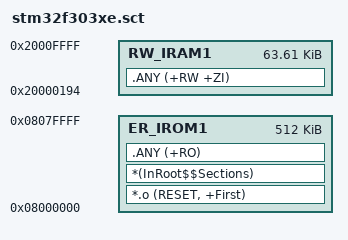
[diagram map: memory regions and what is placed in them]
; Scatter-Loading Description File
;;;;;;;;;;;;;;;;;;;;;;;;;;;;;;;;;;;;;;;;;;;;;;;;;;;;;;;;;;;;;;;;;;;;;;;;;;;;;;;;
; Copyright (c) 2014, STMicroelectronics
; All rights reserved.
;
; Redistribution and use in source and binary forms, with or without
; modification, are permitted provided that the following conditions are met:
;
; 1. Redistributions of source code must retain the above copyright notice,
;     this list of conditions and the following disclaimer.
; 2. Redistributions in binary form must reproduce the above copyright notice,
;    this list of conditions and the following disclaimer in the documentation
;    and/or other materials provided with the distribution.
; 3. Neither the name of STMicroelectronics nor the names of its contributors
;    may be used to endorse or promote products derived from this software
;    without specific prior written permission.
;
; THIS SOFTWARE IS PROVIDED BY THE COPYRIGHT HOLDERS AND CONTRIBUTORS "AS IS"
; AND ANY EXPRESS OR IMPLIED WARRANTIES, INCLUDING, BUT NOT LIMITED TO, THE
; IMPLIED WARRANTIES OF MERCHANTABILITY AND FITNESS FOR A PARTICULAR PURPOSE ARE
; DISCLAIMED. IN NO EVENT SHALL THE COPYRIGHT HOLDER OR CONTRIBUTORS BE LIABLE
; FOR ANY DIRECT, INDIRECT, INCIDENTAL, SPECIAL, EXEMPLARY, OR CONSEQUENTIAL
; DAMAGES (INCLUDING, BUT NOT LIMITED TO, PROCUREMENT OF SUBSTITUTE GOODS OR
; SERVICES; LOSS OF USE, DATA, OR PROFITS; OR BUSINESS INTERRUPTION) HOWEVER
; CAUSED AND ON ANY THEORY OF LIABILITY, WHETHER IN CONTRACT, STRICT LIABILITY,
; OR TORT (INCLUDING NEGLIGENCE OR OTHERWISE) ARISING IN ANY WAY OUT OF THE USE
; OF THIS SOFTWARE, EVEN IF ADVISED OF THE POSSIBILITY OF SUCH DAMAGE.
;;;;;;;;;;;;;;;;;;;;;;;;;;;;;;;;;;;;;;;;;;;;;;;;;;;;;;;;;;;;;;;;;;;;;;;;;;;;;;;;

; STM32F303RE: 512KB FLASH (0x80000) + 64KB SRAM (0x10000)
LR_IROM1 0x08000000 0x80000  {    ; load region size_region

  ER_IROM1 0x08000000 0x80000  {  ; load address = execution address
   *.o (RESET, +First)
   *(InRoot$$Sections)
   .ANY (+RO)
  }

  ; 101 vectors = 404 bytes (0x194) to be reserved in RAM
  RW_IRAM1 (0x20000000+0x194) (0x10000-0x194)  {  ; RW data
   .ANY (+RW +ZI)
  }

}

